# wl_phy_ana_pg_secure register map
Vendor: Texas Instruments
Registers are 32-bit, access per field, reset 0x0 unless marked. A register's access mark holds for its fields unless they carry their own. Offsets are as the file gives them; [hi:lo] are bit positions; {n}, {i} and the like mark numbered series.

## wl_phy_ana_pg_secure (part 2 of 3)
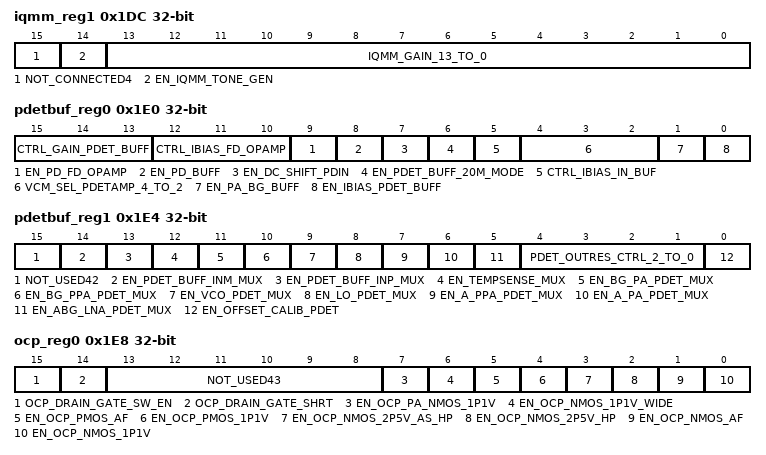
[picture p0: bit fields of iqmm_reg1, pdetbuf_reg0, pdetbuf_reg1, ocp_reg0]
0x1DC iqmm_reg1 — Gain Control bits for IQMM Block
  [15] NOT_CONNECTED4 rw — Not Connected
  [14] EN_IQMM_TONE_GEN rw — Enable the IQMM Block at the Output Tank of LNA
  [13:0] IQMM_GAIN_13_TO_0 rw — Gain Control bits for IQMM Block
0x1E0 pdetbuf_reg0 — Enable IBIAS
  [15:13] CTRL_GAIN_PDET_BUFF rw — Gain control bits for PDET_BUFFER 000 - 8 (18dB) 001 - 5 (14dB) 010 - 4 (12dB) 011 - 2 (6dB) 100 - 1 (0dB) 101 - 0.5 (-6dB) 110 - NA 111 - NA
  [12:10] CTRL_IBIAS_FD_OPAMP rw — Control the bias current in Differential Opamp_ in 12.5uA steps 001 - 12.5uA 100 - 50uA (default) 101 - 62.5uA 110 - 75uA 111 - 87.5uA
  [9] EN_PD_FD_OPAMP rw — Enable Differential Opamp
  [8] EN_PD_BUFF rw — Enable Input Buffers (both Plus and Minus)
  [7] EN_DC_SHIFT_PDIN rw — Enable DC level shift at the PDET_BUFF input_ to reduce the DC by 250mV nominally Suggested if the input levels are more than 600mV. Enabling this block will have 1.2dB attenuation.
  [6] EN_PDET_BUFF_20M_MODE rw — Enable 20M Mode
  [5] CTRL_IBIAS_IN_BUF rw — Increase Input Buffer bias current by 25%
  [4:2] VCM_SEL_PDETAMP_4_TO_2 rw — Select bits for setting the VCM of the PDET_BUFF Output (values are provided for Vref=800mV) 111 - 800mV 110 - 750mV 101 - 700mV 100 - 650mV (default) 011 - 600mV 010 - 550mV 001 - 500mV 000 - 450mV
  [1] EN_PA_BG_BUFF rw — Enable BG BUF (which provides the common mode voltage for setting the PDET_BUFF Output)
  [0] EN_IBIAS_PDET_BUFF rw — Enable IBIAS
0x1E4 pdetbuf_reg1 — Enable Offset calibration switch connected between INP and INM of PDET_BUFF
  [15] NOT_USED42 rw — Spare bit
  [14] EN_PDET_BUFF_INM_MUX rw — Connect PDET_BUFF INM to PDET_TEST_OUT
  [13] EN_PDET_BUFF_INP_MUX rw — Connect PDET_BUFF INP to PDET_TEST_OUT
  [12] EN_TEMPSENSE_MUX rw — Connect RFCIO TSense output to PDET_BUFF inputs
  [11] EN_BG_PA_PDET_MUX rw — Connect BG PA PDet output to PDET_BUFF inputs
  [10] EN_BG_PPA_PDET_MUX rw — Connect BG PPA or BG Mixer PDet output to PDET_BUFF inputs
  [9] EN_VCO_PDET_MUX rw — Connect VCO PDet output to PDET_BUFF inputs
  [8] EN_LO_PDET_MUX rw — Connect A LO Gen PDet output to PDET_BUFF inputs
  [7] EN_A_PPA_PDET_MUX rw — Connect A PPA or A Mixer PDet output to PDET_BUFF inputs
  [6] EN_A_PA_PDET_MUX rw — Connect A PA PDet output to PDET_BUFF inputs
  [5] EN_ABG_LNA_PDET_MUX rw — Connect BG and A LNA PDet output to PDET_BUFF inputs
  [4:1] PDET_OUTRES_CTRL_2_TO_0 rw — Trim bits for the 32k resistor at PD_TOP Output (which is connected to Rx_IFA2 virtual ground) 0000 - Lowest Res 1000 - Default 1111 - Higest Res
  [0] EN_OFFSET_CALIB_PDET rw — Enable Offset calibration switch connected between INP and INM of PDET_BUFF
0x1E8 ocp_reg0 reset not defined — Enable OCP NMOS 1.1V transistor
  [15] OCP_DRAIN_GATE_SW_EN rw — Enable the drain and gate switches of OCP transistors
  [14] OCP_DRAIN_GATE_SHRT rw — Short drain and gate nodes of OCP transistors
  [13:8] NOT_USED43 rw — Spare bits
  [7] EN_OCP_PA_NMOS_1P1V rw — Enable OCP_PA NMOS 1.1V transistor
  [6] EN_OCP_NMOS_1P1V_WIDE rw — Enable OCP NMOS 1.1V Wide transistor
  [5] EN_OCP_PMOS_AF rw — Enable OCP PMOS AF transistor
  [4] EN_OCP_PMOS_1P1V rw — Enable OCP PMOS 1.1V transistor
  [3] EN_OCP_NMOS_2P5V_AS_HP rw — Enable OCP NMOS 2.5V AS HP transistor
  [2] EN_OCP_NMOS_2P5V_HP rw — Enable OCP NMOS 2.5V HP transistor
  [1] EN_OCP_NMOS_AF rw — Enable OCP NMOS AF transistor
  [0] EN_OCP_NMOS_1P1V rw — Enable OCP NMOS 1.1V transistor
0x1EC ocp_reg1 reset 0x4F004F — Not used
  [15:0] OCP_REG1_15_0 rw
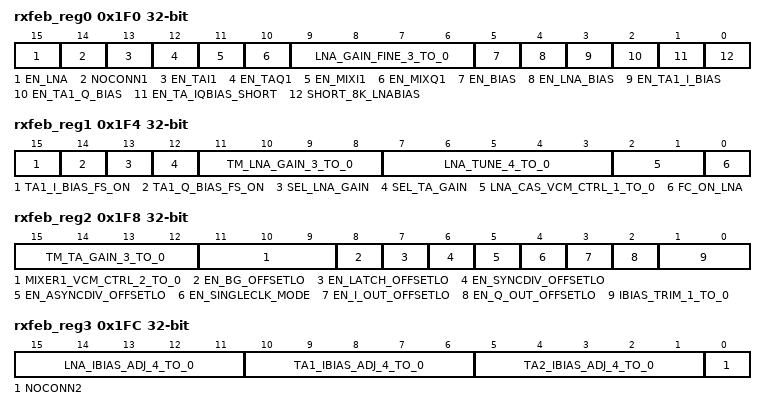
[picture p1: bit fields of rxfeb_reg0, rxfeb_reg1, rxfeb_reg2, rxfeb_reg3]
0x1F0 rxfeb_reg0 — Reduction of LNA bias resistance
  [15] EN_LNA rw — Enable LNA
  [14] NOCONN1 rw — Not Connected
  [13] EN_TAI1 rw — Enable TA I-Channel
  [12] EN_TAQ1 rw — Enable TA Q-Channel
  [11] EN_MIXI1 rw — Enable Mixer I-Channel
  [10] EN_MIXQ1 rw — Enable Mixer Q-Channel
  [9:6] LNA_GAIN_FINE_3_TO_0 rw — Fine Control for LNA Gain Thermometric coded Each bit is LSB of LNA Gain
  [5] EN_BIAS rw — Enable Bias Block
  [4] EN_LNA_BIAS rw — Enable LNA Bias in the Bias Block
  [3] EN_TA1_I_BIAS rw — Enable TA I Channel Bias in the Bias Block
  [2] EN_TA1_Q_BIAS rw — Enable TA Q Channel Bias in the Bias Block
  [1] EN_TA_IQBIAS_SHORT rw — Enable shorting of TA I and Q bias
  [0] SHORT_8K_LNABIAS rw — Reduction of LNA bias resistance
0x1F4 rxfeb_reg1 — Enable Fast Charge LNA
  [15] TA1_I_BIAS_FS_ON rw — Enable Fast Charge TA I-Channel
  [14] TA1_Q_BIAS_FS_ON rw — Enable Fast Charge TA Q-Channel
  [13] SEL_LNA_GAIN rw — Select the LNA gain bits 0 - register bits (TM_LNA_GAIN) will be applied 1 - modem control will be applied
  [12] SEL_TA_GAIN rw — Select the TA gain bits 0 - register bits (TM_TA_GAIN) will be applied 1 - modem control will be applied
  [11:8] TM_LNA_GAIN_3_TO_0 rw — Gain Control bits for LNA 1111 - Highest Gain (Nom 26dB) 0111 - m6dB Gain 0011 - m12dB Gain 0001 - m18dB Gain 0000 - m24dB Gain Gain DNL can vary
  [7:3] LNA_TUNE_4_TO_0 rw — Lna capbank control 00000 - Lowest cap_ Highest frequency tuned 11111 - Highest cap_ lowest frequency tuned 01011 - Nom tunes to 2.45G
  [2:1] LNA_CAS_VCM_CTRL_1_TO_0 rw — Lna cascode gate voltage control 11 - VDDA (1.3V) 10 - 1.2V 01 - 1.1V 00 - 1V
  [0] FC_ON_LNA rw — Enable Fast Charge LNA
0x1F8 rxfeb_reg2 — Control bits to trim the current entering the Bias Block 00 - 50u Ref current (default) 01 - 25u Ref current 10 - 100u Ref current 11 - 33u Ref current
  [15:12] TM_TA_GAIN_3_TO_0 rw — Gain Control for TA 1111 - Highest Gain (Nom 30dB with IFA1) 0111 - m6dB Gain 0011 - m12dB Gain 0001 - m18dB Gain
  [11:9] MIXER1_VCM_CTRL_2_TO_0 rw — Vcm Control for Mixer 111 - 1.21V 110 - 1.13V 101 - 1V 100 - 0.975V 011 - 0.89V 010 - 0.81V 001 - 0.731V 000 - 0.65V
  [8] EN_BG_OFFSETLO rw — Enable offset LO
  [7] EN_LATCH_OFFSETLO rw — Enable latch (To fix starting phase)
  [6] EN_SYNCDIV_OFFSETLO rw — Enable for Synchronous startup mode
  [5] EN_ASYNCDIV_OFFSETLO rw — Enable for Asynchronous startup mode
  [4] EN_SINGLECLK_MODE rw — Enable for Single ended LO input mode 0 - Differential LO input 1 - Single ended LO input
  [3] EN_I_OUT_OFFSETLO rw — Enable for I channel output
  [2] EN_Q_OUT_OFFSETLO rw — Enable for Q channel output
  [1:0] IBIAS_TRIM_1_TO_0 rw — Control bits to trim the current entering the Bias Block 00 - 50u Ref current (default) 01 - 25u Ref current 10 - 100u Ref current 11 - 33u Ref current
0x1FC rxfeb_reg3 — Not connected
  [15:11] LNA_IBIAS_ADJ_4_TO_0 rw — Control for bias of LNA Binary arrangement with ILSB = 20u (Nom)
  [10:6] TA1_IBIAS_ADJ_4_TO_0 rw — Control for bias of TA I Channel Binary arrangement with ILSB = 5u (Nom)
  [5:1] TA2_IBIAS_ADJ_4_TO_0 rw — Control for bias of TA Q Channel Binary Arrangement with ILSB=5u (Nom)
  [0] NOCONN2 rw — Not connected
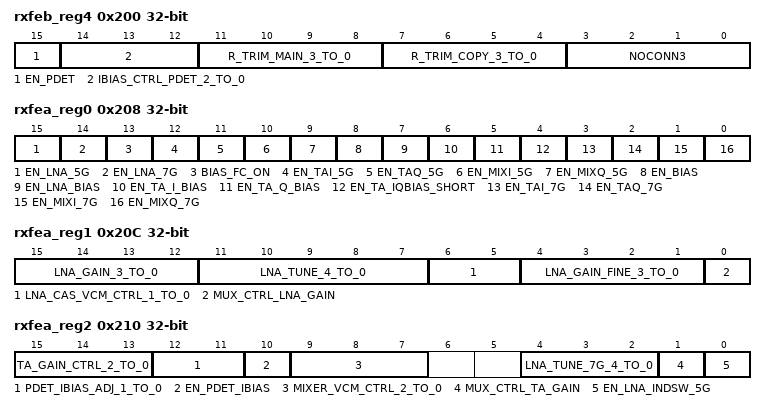
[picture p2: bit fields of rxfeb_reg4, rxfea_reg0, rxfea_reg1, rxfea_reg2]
0x200 rxfeb_reg4 — Not connected
  [15] EN_PDET rw — Enable bit for PDET at LNA output
  [14:12] IBIAS_CTRL_PDET_2_TO_0 rw — Ibias control for PDET at LNA output
  [11:8] R_TRIM_MAIN_3_TO_0 rw — Resistor trim bits for the main branch
  [7:4] R_TRIM_COPY_3_TO_0 rw — Resistor trim bits for the replica branch
  [3:0] NOCONN3 rw — Not connected
0x204 rxpdetb_reg0 reset 0x210021 — MEM_RXPDETB_REG0
  [15:0] RXPDETB_REG0_15_0 rw
0x208 rxfea_reg0 — Enable bit for 7G P-Mixer Q-Channel
  [15] EN_LNA_5G rw — Enable bit for LNA 5G
  [14] EN_LNA_7G rw — Enable bit for LNA 7G
  [13] BIAS_FC_ON rw — Enable bit for Fast Charge LNA
  [12] EN_TAI_5G rw — Enable bit for 5G TA I-Channel
  [11] EN_TAQ_5G rw — Enable bit for 5G TA Q-Channel
  [10] EN_MIXI_5G rw — Enable bit for 5G P-Mixer I-Channel
  [9] EN_MIXQ_5G rw — Enable bit for 5G P-Mixer Q-Channel
  [8] EN_BIAS rw — Enable bit for Bias Block
  [7] EN_LNA_BIAS rw — Enable bit for LNA Bias in the Bias Block
  [6] EN_TA_I_BIAS rw — Enable bit for TA I ch Bias in the Bias Block
  [5] EN_TA_Q_BIAS rw — Enable bit for TA Q ch Bias in the Bias Block
  [4] EN_TA_IQBIAS_SHORT rw — Enable TA_IQBIAS_SHORT
  [3] EN_TAI_7G rw — Enable bit for 7G TA I-Channel
  [2] EN_TAQ_7G rw — Enable bit for 7G TA Q-Channel
  [1] EN_MIXI_7G rw — Enable bit for 7G P-Mixer I-Channel
  [0] EN_MIXQ_7G rw — Enable bit for 7G P-Mixer Q-Channel
0x20C rxfea_reg1 — Mux Control to select either Modem Input or Register Input for LNA Gain 0 - Modem Input 1 - Register Input
  [15:12] LNA_GAIN_3_TO_0 rw — Gain Control bits for LNA 1111 - Highest Gain (Nom 23dB) 0111 - m6dB Gain 0011 - m12dB Gain 0001 - m18dB Gain 0000 - m24dB Gain Gain DNL can vary
  [11:7] LNA_TUNE_4_TO_0 rw — Lna capbank control for 5G 00000 - Lowest cap _ Highest frequency tuned 11111 - Highest cap _ lowest frequency tuned 01111 - Nom tunes to 5G
  [6:5] LNA_CAS_VCM_CTRL_1_TO_0 rw — Lna cascode gate voltage control 11 - VDD(1.3V) 10 - 1.2V 01 - 1.1V 00 - 1V
  [4:1] LNA_GAIN_FINE_3_TO_0 rw — Fine Control for LNA Gain Thermometric coded Each bit is LSB of LNA Gain Default - 2*LSB On
  [0] MUX_CTRL_LNA_GAIN rw — Mux Control to select either Modem Input or Register Input for LNA Gain 0 - Modem Input 1 - Register Input
0x210 rxfea_reg2 — In 5G mode_ enable the switch to short 7G coil to supply
  [15:13] TA_GAIN_CTRL_2_TO_0 rw — Gain Control for TA I Channel 111- Highest Gain ( Nom 30dB with IFA1) 011- m6dB Gain 001 - m12dB Gain 000 - m18dB Gain
  [12:11] PDET_IBIAS_ADJ_1_TO_0 rw — Control the bias current into the PDET Block at the Output of LNA 2 - bit Binary arrangement 10 - 10uA (Nominal) 11 - 15uA 01- 5uA
  [10] EN_PDET_IBIAS rw — Enable the Ibias for PDET Block at the output of LNA
  [9:7] MIXER_VCM_CTRL_2_TO_0 rw — Vcm Control for Pmixer 111 - 1.21V 110 - 1.13V 101 - 1V 100 - 0.975V 011 - 0.89V 010 - 0.81V 001 - 0.731V 000 - 0.65V
  [4:2] LNA_TUNE_7G_4_TO_0 rw — Lna capbank control for 7G 00000 - Lowest cap _ Highest frequency tuned 11111 - Highest cap _ lowest frequency tuned 01111 - Nom tunes to 7G
  [1] MUX_CTRL_TA_GAIN rw — Mux Control to select either Modem Input or Register Input for TA Gain 0 - Modem Input 1 - Register Input
  [0] EN_LNA_INDSW_5G rw — In 5G mode_ enable the switch to short 7G coil to supply
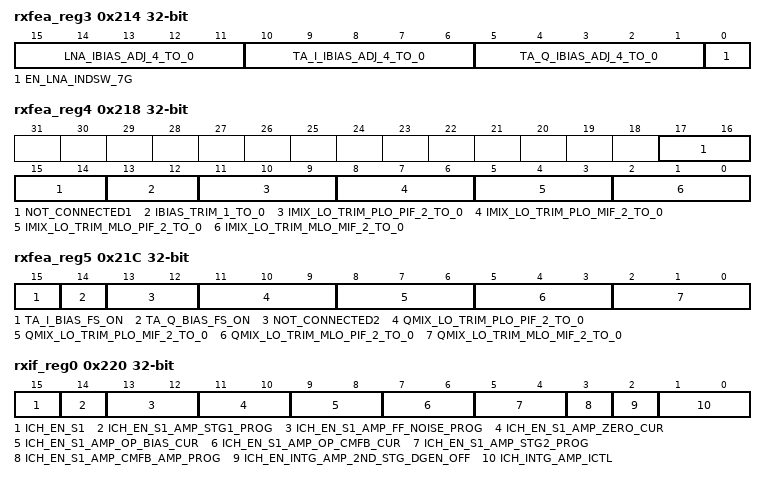
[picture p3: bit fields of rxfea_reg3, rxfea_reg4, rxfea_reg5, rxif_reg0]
0x214 rxfea_reg3 — In 7G mode_ enable the switch to short 5G coil to supply
  [15:11] LNA_IBIAS_ADJ_4_TO_0 rw — Control for bias of A LNA Binary arrangement with ILSB = 40u (Nom)
  [10:6] TA_I_IBIAS_ADJ_4_TO_0 rw — Control for bias of TA I Channel Binary arrangement with ILSB = 5u (Nom)
  [5:1] TA_Q_IBIAS_ADJ_4_TO_0 rw — Control for bias of TA Q Channel Binary Arrangement with ILSB=5u (Nom)
  [0] EN_LNA_INDSW_7G rw — In 7G mode_ enable the switch to short 5G coil to supply
0x218 rxfea_reg4 — Trim control for PMIX Ich connected to LOM and IFM . Coarse Trim decides the tap point .This is Fine Trim. 100-Mid code 011 - 10mV Lower 101- 10mV higher
  [17:14] NOT_CONNECTED1 rw — Not Connected
  [13:12] IBIAS_TRIM_1_TO_0 rw — Control bits to trim the current entering the Bias Block 00 - 50u Ref current(default) 01 - 25u Ref current 10 - 100u Ref current 11 - 33u Ref current
  [11:9] IMIX_LO_TRIM_PLO_PIF_2_TO_0 rw — Trim control for PMIX Ich connected to LOP and IFP . Coarse Trim decides the tap point .This is Fine Trim. 100-Mid code 011 - 10mV Lower 101- 10mV higher
  [8:6] IMIX_LO_TRIM_PLO_MIF_2_TO_0 rw — Trim control for PMIX Ich connected to LOP and IFM . Coarse Trim decides the tap point .This is Fine Trim. 100-Mid code 011 - 10mV Lower 101- 10mV higher
  [5:3] IMIX_LO_TRIM_MLO_PIF_2_TO_0 rw — Trim control for PMIX Ich connected to LOM and IFP . Coarse Trim decides the tap point .This is Fine Trim. 100-Mid code 011 - 10mV Lower 101- 10mV higher
  [2:0] IMIX_LO_TRIM_MLO_MIF_2_TO_0 rw — Trim control for PMIX Ich connected to LOM and IFM . Coarse Trim decides the tap point .This is Fine Trim. 100-Mid code 011 - 10mV Lower 101- 10mV higher
0x21C rxfea_reg5 — Trim control for PMIX Qch connected to LOM and IFM . Coarse Trim decides the tap point .This is Fine Trim. 100-Mid code 011 - 10mV Lower 101- 10mV higher
  [15] TA_I_BIAS_FS_ON rw — 0
  [14] TA_Q_BIAS_FS_ON rw — 0
  [13:12] NOT_CONNECTED2 rw — Not Connected
  [11:9] QMIX_LO_TRIM_PLO_PIF_2_TO_0 rw — Trim control for PMIX Qch connected to LOP and IFP . Coarse Trim decides the tap point .This is Fine Trim. 100-Mid code 011 - 10mV Lower 101- 10mV higher
  [8:6] QMIX_LO_TRIM_PLO_MIF_2_TO_0 rw — Trim control for PMIX Qch connected to LOP and IFM . Coarse Trim decides the tap point .This is Fine Trim. 100-Mid code 011 - 10mV Lower 101- 10mV higher
  [5:3] QMIX_LO_TRIM_MLO_PIF_2_TO_0 rw — Trim control for PMIX Qch connected to LOM and IFP . Coarse Trim decides the tap point .This is Fine Trim. 100-Mid code 011 - 10mV Lower 101- 10mV higher
  [2:0] QMIX_LO_TRIM_MLO_MIF_2_TO_0 rw — Trim control for PMIX Qch connected to LOM and IFM . Coarse Trim decides the tap point .This is Fine Trim. 100-Mid code 011 - 10mV Lower 101- 10mV higher
0x220 rxif_reg0 — INTG Bias current Programmability 00=8uA (8_10) 01=10uA (8_8) 10=11.4uA (8_7) 11=13.3uA(8_6)
  [15] ICH_EN_S1 rw — Enable Integrator
  [14] ICH_EN_S1_AMP_STG1_PROG rw — Second Arm of INT Stage 1- Gain Programmability
  [13:12] ICH_EN_S1_AMP_FF_NOISE_PROG rw — INTG Active zero -(no of gm_gm stage arms) 00= Active Zero Disabled 1_01 = One ARM 11= Both ARMs
  [11:10] ICH_EN_S1_AMP_ZERO_CUR rw — Active Zero NMOS Device (S2 of Main AMP) ARMS 00= No Arm 01_10=One ARM 11= Both ARMS
  [9:8] ICH_EN_S1_AMP_OP_BIAS_CUR rw — INTG S2 current 00= Base Current 01=+100uA 11= +200uA
  [7:6] ICH_EN_S1_AMP_OP_CMFB_CUR rw — CMFB Stage 2 (NMOS) arms
  [5:4] ICH_EN_S1_AMP_STG2_PROG rw — Stage 2 Number of Arms 00= No Arm 01_10=One ARM 11= Both ARMS
  [3] ICH_EN_S1_AMP_CMFB_AMP_PROG rw — CMFB Stage 1 arms 0 Single ARM 1 Both ARMS
  [2] ICH_EN_INTG_AMP_2ND_STG_DGEN_OFF rw — 0= DGEN ENABLE 1= DGEN ENABLE
  [1:0] ICH_INTG_AMP_ICTL rw — INTG Bias current Programmability 00=8uA (8_10) 01=10uA (8_8) 10=11.4uA (8_7) 11=13.3uA(8_6)
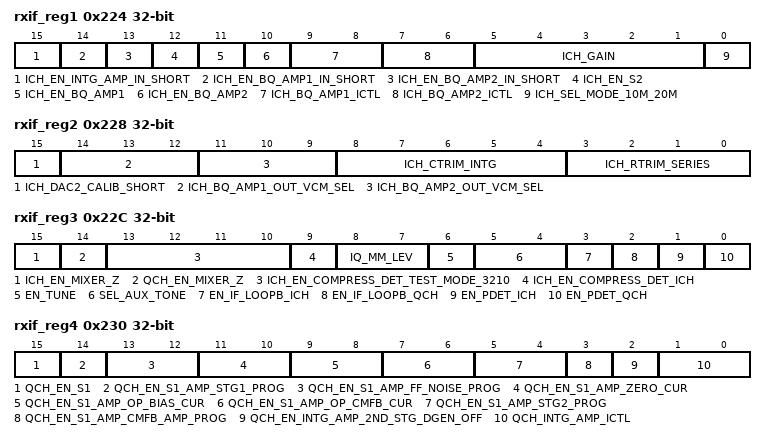
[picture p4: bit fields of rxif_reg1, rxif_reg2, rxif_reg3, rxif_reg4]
0x224 rxif_reg1 — Cap Mode 0 = HIGH CAP 1= LOW CAP
  [15] ICH_EN_INTG_AMP_IN_SHORT rw — Pull down INTG Inp
  [14] ICH_EN_BQ_AMP1_IN_SHORT rw — Pull down BQ1 Inp
  [13] ICH_EN_BQ_AMP2_IN_SHORT rw — Pull down BQ2 Inp
  [12] ICH_EN_S2 rw — Enable BiQuad
  [11] ICH_EN_BQ_AMP1 rw — ENABLE BQ1 amp
  [10] ICH_EN_BQ_AMP2 rw — ENABLE BQ2 amp
  [9:8] ICH_BQ_AMP1_ICTL rw — Biquad Bias current Programmability 00=8uA (8_10) 01=10uA (8_8) 10=11.4uA (8_7) 11=13.3uA(8_6)
  [7:6] ICH_BQ_AMP2_ICTL rw — Biquad Bias current Programmability 00=8uA (8_10) 01=10uA (8_8) 10=11.4uA (8_7) 11=13.3uA(8_6)
  [5:1] ICH_GAIN rw — Gain 00000=-7dB 00001=-6dB 00010=-5dB... 00101=-2dB (NOM MIN) 01101=6dB (NOM MAX) 10010=11dB 10011=12dB 10100=13dB 10101=14dB 10110=15dB 10111=16dB 11000=17dB (AUX RX MODE) 11001=20dB (AUX RX MODE) 11010=23dB (AUX RX MODE)
  [0] ICH_SEL_MODE_10M_20M rw — Cap Mode 0 = HIGH CAP 1= LOW CAP
0x228 rxif_reg2 — Sereis Rtrrim 0000 MIN R=( WEAK CORNER) 1001 NOM R 1111 MAX R (STRONG CORNER)
  [15] ICH_DAC2_CALIB_SHORT rw — Short imp inm of Biquad
  [14:12] ICH_BQ_AMP1_OUT_VCM_SEL rw — VCM BQ amp1 000=330mV 001=360mV 100=450mV (NOM) 111=540mV
  [11:9] ICH_BQ_AMP2_OUT_VCM_SEL rw — VCM BQ amp2 000=330mV 001=360mV 100=450mV (NOM) 111=540mV
  [8:4] ICH_CTRIM_INTG rw — Cint Cap tune 00000= Min CAP 01001= NOM CAP 11111= MAX CAP
  [3:0] ICH_RTRIM_SERIES rw — Sereis Rtrrim 0000 MIN R=( WEAK CORNER) 1001 NOM R 1111 MAX R (STRONG CORNER)
0x22C rxif_reg3 — ENABLE PDET
  [15] ICH_EN_MIXER_Z rw — Add input impedance to INTG
  [14] QCH_EN_MIXER_Z rw — Add input impedance to INTG
  [13:10] ICH_EN_COMPRESS_DET_TEST_MODE_3210 rw — Mux Compress det out on test mode 0000= NO O_p 0001= DETECTOR O_P To TEST PIN 0010= Compare Ref O_P to Test Pin 0100=Compare input (PEAK det) O_P to Test PIN 1000= VCM input to Test PIN
  [9] ICH_EN_COMPRESS_DET_ICH rw — EN Compress DET
  [8:7] IQ_MM_LEV rw — BW calib DAC power 00=5uA 01=10uA 10=15uA 11=20uA
  [6] EN_TUNE rw — EN BW Calib DAC
  [5:4] SEL_AUX_TONE rw — Bandwidth calib DAC FREQ SEL 00=2.5MHz 01=5MHz 10=10MHz 11=20MHz
  [3] EN_IF_LOOPB_ICH rw — EN TX Loopback
  [2] EN_IF_LOOPB_QCH rw — EN TX Loopback
  [1] EN_PDET_ICH rw — ENABLE PDET
  [0] EN_PDET_QCH rw — ENABLE PDET
0x230 rxif_reg4 — INTG Bias current Programmability 00=8uA (8_10) 01=10uA (8_8) 10=11.4uA (8_7) 11=13.3uA(8_6)
  [15] QCH_EN_S1 rw — Enable Integrator
  [14] QCH_EN_S1_AMP_STG1_PROG rw — Second Arm of INT Stage 1- Gain Programmability
  [13:12] QCH_EN_S1_AMP_FF_NOISE_PROG rw — INTG Active zero -(no of gm_gm stage arms) 00= Active Zero Disabled 1_01 = One ARM 11= Both ARMs
  [11:10] QCH_EN_S1_AMP_ZERO_CUR rw — Active Zero NMOS Device (S2 of Main AMP) ARMS 00= No Arm 01_10=One ARM 11= Both ARMS
  [9:8] QCH_EN_S1_AMP_OP_BIAS_CUR rw — INTG S2 current 00= Base Current 01=+100uA 11= +200uA
  [7:6] QCH_EN_S1_AMP_OP_CMFB_CUR rw — CMFB Stage 2 (NMOS) arms
  [5:4] QCH_EN_S1_AMP_STG2_PROG rw — Stage 2 Number of Arms 00= No Arm 01_10=One ARM 11= Both ARMS
  [3] QCH_EN_S1_AMP_CMFB_AMP_PROG rw — CMFB Stage 1 arms 0 Single ARM 1 Both ARMS
  [2] QCH_EN_INTG_AMP_2ND_STG_DGEN_OFF rw — 0= DGEN ENABLE 1= DGEN ENABLE
  [1:0] QCH_INTG_AMP_ICTL rw — INTG Bias current Programmability 00=8uA (8_10) 01=10uA (8_8) 10=11.4uA (8_7) 11=13.3uA(8_6)
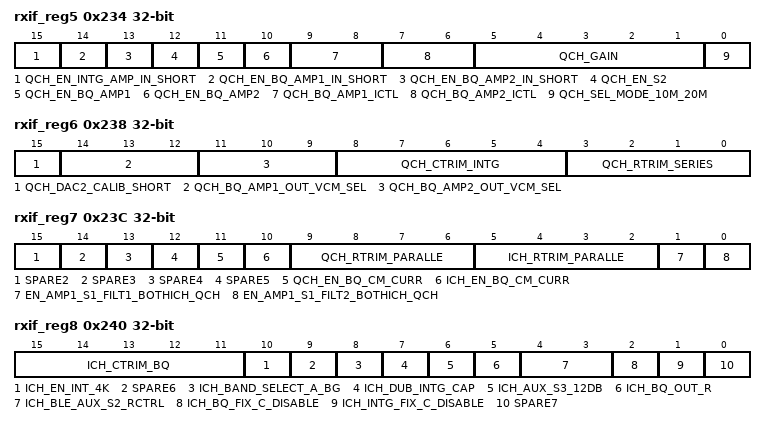
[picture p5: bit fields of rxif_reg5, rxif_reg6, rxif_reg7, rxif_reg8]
0x234 rxif_reg5 — Cap Mode 0 = HIGH CAP 1= LOW CAP
  [15] QCH_EN_INTG_AMP_IN_SHORT rw — Pull down INTG Inp
  [14] QCH_EN_BQ_AMP1_IN_SHORT rw — Pull down BQ1 Inp
  [13] QCH_EN_BQ_AMP2_IN_SHORT rw — Pull down BQ2 Inp
  [12] QCH_EN_S2 rw — Enable BiQuad
  [11] QCH_EN_BQ_AMP1 rw — ENABLE BQ1 amp
  [10] QCH_EN_BQ_AMP2 rw — ENABLE BQ2 amp
  [9:8] QCH_BQ_AMP1_ICTL rw — Biquad Bias current Programmability 00=8uA (8_10) 01=10uA (8_8) 10=11.4uA (8_7) 11=13.3uA(8_6)
  [7:6] QCH_BQ_AMP2_ICTL rw — Biquad Bias current Programmability 00=8uA (8_10) 01=10uA (8_8) 10=11.4uA (8_7) 11=13.3uA(8_6)
  [5:1] QCH_GAIN rw — Gain 00000=-7dB 00001=-6dB 00010=-5dB... 00101=-2dB (NOM MIN) 01101=6dB (NOM MAX) 10010=11dB 10011=12dB 10100=13dB 10101=14dB 10110=15dB 10111=16dB 11000=17dB (AUX RX MODE) 11001=20dB (AUX RX MODE) 11010=23dB (AUX RX MODE)
  [0] QCH_SEL_MODE_10M_20M rw — Cap Mode 0 = HIGH CAP 1= LOW CAP
0x238 rxif_reg6 — Sereis Rtrrim 0000 MIN R=( WEAK CORNER) 1001 NOM R 1111 MAX R (STRONG CORNER)
  [15] QCH_DAC2_CALIB_SHORT rw — Short imp inm of Biquad
  [14:12] QCH_BQ_AMP1_OUT_VCM_SEL rw — VCM BQ amp1 000=330mV 001=360mV 100=450mV (NOM) 111=540mV
  [11:9] QCH_BQ_AMP2_OUT_VCM_SEL rw — VCM BQ amp2 000=330mV 001=360mV 100=450mV (NOM) 111=540mV
  [8:4] QCH_CTRIM_INTG rw — Cint Cap tune 00000= Min CAP 01001= NOM CAP 11111= MAX CAP
  [3:0] QCH_RTRIM_SERIES rw — Sereis Rtrrim 0000 MIN R=( WEAK CORNER) 1001 NOM R 1111 MAX R (STRONG CORNER)
0x23C rxif_reg7 — EN RC2(Low Cap) at intg S1 O_p
  [17-n] SPARE{n} rw (n=2..5) — SPARE
  [11] QCH_EN_BQ_CM_CURR rw — Q Boost BQ input CM
  [10] ICH_EN_BQ_CM_CURR rw — I Boost BQ input CM
  [9:6] QCH_RTRIM_PARALLE rw — Parallel Rtrim 0000= MAX R (STRONG CORNER) 0100= NOM R 1111=MIN R
  [5:2] ICH_RTRIM_PARALLE rw — Parallel Rtrim 0000= MAX R (STRONG CORNER) 0100= NOM R 1111=MIN R
  [1] EN_AMP1_S1_FILT1_BOTHICH_QCH rw — EN Low RC1 (High cap) at INTG S1 O_p
  [0] EN_AMP1_S1_FILT2_BOTHICH_QCH rw — EN RC2(Low Cap) at intg S1 O_p
0x240 rxif_reg8
  [15:11] ICH_CTRIM_BQ rw — C BQ Cap tune 00000= MIN CAP 01001=NOM CAP 11111= MAX CAP
  [10] ICH_EN_INT_4K rw — INTG RFb 4k_8k 0=8k 1=4k
  [9] SPARE6 rw — Input path Select Rx_ Aux Rx 0= WLAN_BLE Rx 1= AUX Rx
  [8] ICH_BAND_SELECT_A_BG rw — Input path select (Band-a_BG) 0= BG 1= A
  [7] ICH_DUB_INTG_CAP rw — INTG C feedback double 0= Normal CAP 1= Double CAP
  [6] ICH_AUX_S3_12DB rw — Aux Rx gain S3 0= Nominal gain 1= +6dB
  [5] ICH_BQ_OUT_R rw — Open biquad outer loop 1= WLAN MODE 0= BLE + AUXRX MODE
  [4:3] ICH_BLE_AUX_S2_RCTRL rw — BQ Amp1 Rfb control 00=16k 01=20.1k 10=25.44k 11=32k
  [2] ICH_BQ_FIX_C_DISABLE rw — Fixed Cap disable BQ
  [1] ICH_INTG_FIX_C_DISABLE rw — Fixed Cap disable INTG
  [0] SPARE7 rw
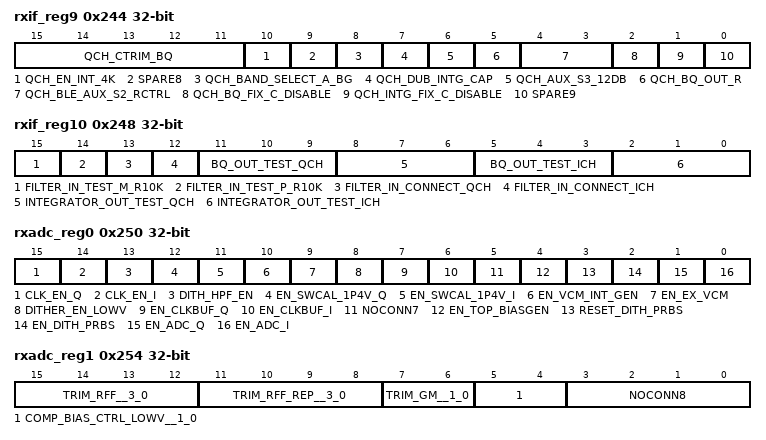
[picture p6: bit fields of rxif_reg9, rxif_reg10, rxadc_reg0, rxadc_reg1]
0x244 rxif_reg9
  [15:11] QCH_CTRIM_BQ rw — C BQ Cap tune 00000= MIN CAP 01001=NOM CAP 11111= MAX CAP
  [10] QCH_EN_INT_4K rw — INTG RFb 4k_8k 0=8k 1=4k
  [9] SPARE8 rw — Input path Select Rx_ Aux Rx 0= WLAN_BLE Rx 1= AUX Rx
  [8] QCH_BAND_SELECT_A_BG rw — Input path select (Band-a_BG) 0= BG 1= A
  [7] QCH_DUB_INTG_CAP rw — INTG C feedback double 0= Normal CAP 1= Double CAP
  [6] QCH_AUX_S3_12DB rw — Aux Rx gain S3 0= Nominal gain 1= +6dB
  [5] QCH_BQ_OUT_R rw — Open biquad outer loop 1= WLAN MODE 0= BLE + AUXRX MODE
  [4:3] QCH_BLE_AUX_S2_RCTRL rw — BQ Amp1 Rfb control 00=16k 01=20.1k 10=25.44k 11=32k
  [2] QCH_BQ_FIX_C_DISABLE rw — Fixed Cap disable BQ
  [1] QCH_INTG_FIX_C_DISABLE rw — Fixed Cap disable INTG
  [0] SPARE9 rw
0x248 rxif_reg10 — 001-EN_I_SENSE 010-EN_V_SENSE 100-EN_EXT_INP through R=400
  [15] FILTER_IN_TEST_M_R10K rw — Connects a 10K R From TestM to GND
  [14] FILTER_IN_TEST_P_R10K rw — Connects a 10K R From TestP to GND
  [13] FILTER_IN_CONNECT_QCH rw — Connects QCH to TestP and TestM
  [12] FILTER_IN_CONNECT_ICH rw — Connects ICH to TestP and TestM
  [11:9] BQ_OUT_TEST_QCH rw — 001-EN_I_SENSE 010-EN_V_SENSE_ADC_TEST_IN 100-EN_EXT_INP through R=8k
  [8:6] INTEGRATOR_OUT_TEST_QCH rw — 001-EN_I_SENSE 010-EN_V_SENSE 100-EN_EXT_INP through R=400
  [5:3] BQ_OUT_TEST_ICH rw — 001-EN_I_SENSE 010-EN_V_SENSE_ADC_TEST_IN 100-EN_EXT_INP through R=8k
  [2:0] INTEGRATOR_OUT_TEST_ICH rw — 001-EN_I_SENSE 010-EN_V_SENSE 100-EN_EXT_INP through R=400
0x24C rxv2i_reg0 reset 0x220022 — MEM_RXV2I_REG0
  [15:0] RXV2I_REG0_15_0 rw
0x250 rxadc_reg0 — I channel
  [15] CLK_EN_Q rw — Q channel
  [14] CLK_EN_I rw — I channel
  [13] DITH_HPF_EN rw — both
  [12] EN_SWCAL_1P4V_Q rw — Q channel
  [11] EN_SWCAL_1P4V_I rw — I channel
  [10] EN_VCM_INT_GEN rw — both
  [9] EN_EX_VCM rw — both
  [8] DITHER_EN_LOWV rw — both
  [7] EN_CLKBUF_Q rw — Q channel
  [6] EN_CLKBUF_I rw — I channel
  [5] NOCONN7 rw
  [4] EN_TOP_BIASGEN rw — both
  [3] RESET_DITH_PRBS rw — both
  [2] EN_DITH_PRBS rw — both
  [1] EN_ADC_Q rw — Q channel
  [0] EN_ADC_I rw — I channel
0x254 rxadc_reg1
  [15:12] TRIM_RFF__3_0 rw — both
  [11:8] TRIM_RFF_REP__3_0 rw — both
  [7:6] TRIM_GM__1_0 rw — Trim Gm
  [5:4] COMP_BIAS_CTRL_LOWV__1_0 rw — both
  [3:0] NOCONN8 rw
0x258 rxadc_reg2 — I channel
  [15:0] TRIM_SWCAL_1P4V_Q__15_0 rw
0x25C rxadc_reg3 — I channel
  [15:0] TRIM_SWCAL_1P4V_I__15_0 rw
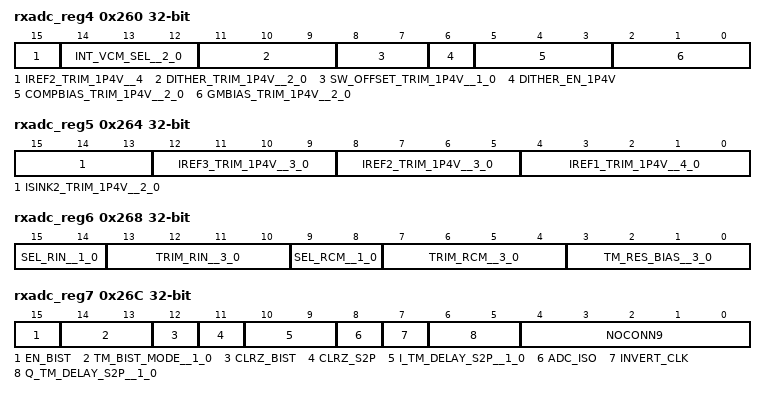
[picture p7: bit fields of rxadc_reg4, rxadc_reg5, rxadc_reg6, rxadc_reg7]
0x260 rxadc_reg4 — Top_Ibias
  [15] IREF2_TRIM_1P4V__4 rw — iref2 trim
  [14:12] INT_VCM_SEL__2_0 rw — int vcm sel
  [11:9] DITHER_TRIM_1P4V__2_0 rw — Top_Ibias
  [8:7] SW_OFFSET_TRIM_1P4V__1_0 rw — Top_Ibias
  [6] DITHER_EN_1P4V rw — Top_Ibias
  [5:3] COMPBIAS_TRIM_1P4V__2_0 rw — Top_Ibias
  [2:0] GMBIAS_TRIM_1P4V__2_0 rw — Top_Ibias
0x264 rxadc_reg5 — Top_Ibias
  [15:13] ISINK2_TRIM_1P4V__2_0 rw — Top_Ibias
  [12:9] IREF3_TRIM_1P4V__3_0 rw — Top_Ibias
  [8:5] IREF2_TRIM_1P4V__3_0 rw — Top_Ibias
  [4:0] IREF1_TRIM_1P4V__4_0 rw — Top_Ibias
0x268 rxadc_reg6 — TM_RES_BIAS
  [15:14] SEL_RIN__1_0 rw — SEL_RIN
  [13:10] TRIM_RIN__3_0 rw — TRIM_RIN
  [9:8] SEL_RCM__1_0 rw — I channel
  [7:4] TRIM_RCM__3_0 rw — Q channel
  [3:0] TM_RES_BIAS__3_0 rw — TM_RES_BIAS
0x26C rxadc_reg7
  [15] EN_BIST rw
  [14:13] TM_BIST_MODE__1_0 rw — TM_BIST_MODE
  [12] CLRZ_BIST rw
  [11] CLRZ_S2P rw
  [10:9] I_TM_DELAY_S2P__1_0 rw — I channel
  [8] ADC_ISO rw
  [7] INVERT_CLK rw
  [6:5] Q_TM_DELAY_S2P__1_0 rw — Q channel
  [4:0] NOCONN9 rw
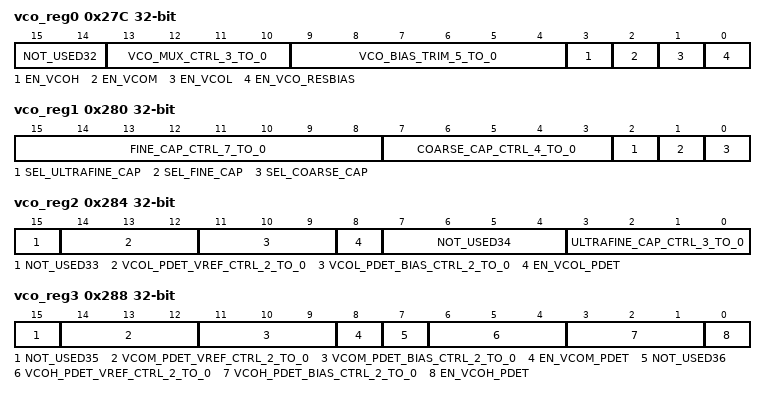
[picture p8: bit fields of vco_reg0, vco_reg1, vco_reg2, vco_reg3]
0x27C vco_reg0 — Enable bit for the VCO Resistor Bias (common for all VCOs)
  [15:14] NOT_USED32 rw — Spare bits
  [13:10] VCO_MUX_CTRL_3_TO_0 rw — Control bits for the VCO MUX_ for selecting different VCO outputs - VCOH - VCOM - VCOL
  [9:4] VCO_BIAS_TRIM_5_TO_0 rw — Trim bits for the VCO Resistor Bias (common control for all VCO currents) Nom_27C_1.3V supply- - 800uA - 1.5mA - 2.7mA - 4.6mA - 7.3mA - 10.5mA
  [3] EN_VCOH rw — Enable bit for the VCOH (8.60-9.50GHz)
  [2] EN_VCOM rw — Enable bit for the VCOM (7.85-8.70GHz)
  [1] EN_VCOL rw — Enable bit for the VCOL (6.40-7.16GHz)
  [0] EN_VCO_RESBIAS rw — Enable bit for the VCO Resistor Bias (common for all VCOs)
0x280 vco_reg1 — Select Coarse Cap control bits to come from 0 - PLL 1 - Register bits (bypass mode)
  [15:8] FINE_CAP_CTRL_7_TO_0 rw — Fine Cap control bits in bypass mode (thermometric arrangement)
  [7:3] COARSE_CAP_CTRL_4_TO_0 rw — Coarse Cap control bits in bypass mode (binary arrangement)
  [2] SEL_ULTRAFINE_CAP rw — Select UltraFine Cap control bits to come from 0 - PLL 1 - Register bits (bypass mode)
  [1] SEL_FINE_CAP rw — Select Fine Cap control bits to come from 0 - PLL 1 - Register bits (bypass mode)
  [0] SEL_COARSE_CAP rw — Select Coarse Cap control bits to come from 0 - PLL 1 - Register bits (bypass mode)
0x284 vco_reg2 — UltraFine Cap control bits in bypass mode (thermometric arrangement)
  [15] NOT_USED33 rw — Spare bit
  [14:12] VCOL_PDET_VREF_CTRL_2_TO_0 rw — Control the VCOL PDet reference voltage by changing the bias diode current_ in steps of 5uA 000 - 10uA 010 - 20uA (default) 111 - 45uA
  [11:9] VCOL_PDET_BIAS_CTRL_2_TO_0 rw — Control the VCOL PDet bias current_ in steps of 5uA 000 - 10uA 010 - 20uA (default) 111 - 45uA
  [8] EN_VCOL_PDET rw — Enable bit for the VCOL PDet
  [7:4] NOT_USED34 rw — Spare bits
  [3:0] ULTRAFINE_CAP_CTRL_3_TO_0 rw — UltraFine Cap control bits in bypass mode (thermometric arrangement)
0x288 vco_reg3 — Enable bit for the VCOH PDet
  [15] NOT_USED35 rw — Spare bit
  [14:12] VCOM_PDET_VREF_CTRL_2_TO_0 rw — Control the VCOM PDet reference voltage by changing the bias diode current_ in steps of 5uA 000 - 10uA 010 - 20uA (default) 111 - 45uA
  [11:9] VCOM_PDET_BIAS_CTRL_2_TO_0 rw — Control the VCOM PDet bias current_ in steps of 5uA 000 - 10uA 010 - 20uA (default) 111 - 45uA
  [8] EN_VCOM_PDET rw — Enable bit for the VCOM PDet
  [7] NOT_USED36 rw — Spare bit
  [6:4] VCOH_PDET_VREF_CTRL_2_TO_0 rw — Control the VCOH PDet reference voltage by changing the bias diode current_ in steps of 5uA 000 - 10uA 010 - 20uA (default) 111 - 45uA
  [3:1] VCOH_PDET_BIAS_CTRL_2_TO_0 rw — Control the VCOH PDet bias current_ in steps of 5uA 000 - 10uA 010 - 20uA (default) 111 - 45uA
  [0] EN_VCOH_PDET rw — Enable bit for the VCOH PDet
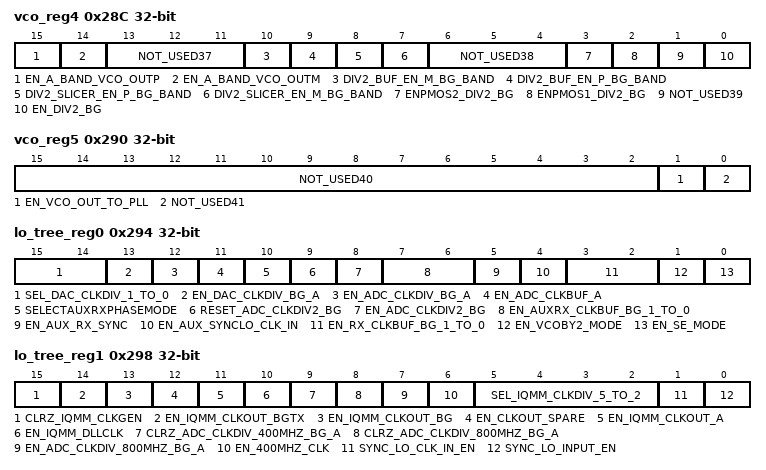
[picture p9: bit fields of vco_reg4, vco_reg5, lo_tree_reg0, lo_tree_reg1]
0x28C vco_reg4 — Enable BG band Div2
  [15] EN_A_BAND_VCO_OUTP rw — Enable VCO_OUTP path to A band LO dist.This needs to be disabled for single ended LO routing mode for vco buffers to a-band
  [14] EN_A_BAND_VCO_OUTM rw — Enable VCO_OUTM path to A band LO dist. This needs to be enabled for single ended LO routing mode for vco buffers to a-band.
  [13:11] NOT_USED37 rw — NOT USED
  [10] DIV2_BUF_EN_M_BG_BAND rw — Enable for OUTM of buf after Slicer (after Div2) for BG band
  [9] DIV2_BUF_EN_P_BG_BAND rw — Enable for OUTP of buf after Slicer (after Div2) for BG band
  [8] DIV2_SLICER_EN_P_BG_BAND rw — Enable for OUTP of Slicer after Div2 for BG band
  [7] DIV2_SLICER_EN_M_BG_BAND rw — Enable for OUTM of Slicer after Div2 for BG band
  [6:4] NOT_USED38 rw — NOT USED
  [3] ENPMOS2_DIV2_BG rw — Enable extra drive for PMOS in BG band Div2 (2X strength)
  [2] ENPMOS1_DIV2_BG rw — Enable extra drive for PMOS in BG band Div2 (1X strength)
  [1] NOT_USED39 rw
  [0] EN_DIV2_BG rw — Enable BG band Div2
0x290 vco_reg5
  [15:2] NOT_USED40 rw — NOT USED
  [1] EN_VCO_OUT_TO_PLL rw — Enable VCO Out to PLL
  [0] NOT_USED41 rw
0x294 lo_tree_reg0 — Enable single ended LO routing mode for VCO clock to a-band
  [15:14] SEL_DAC_CLKDIV_1_TO_0 rw — DAC Divider options 00 - Div4 01 - Div3 10 - Div5 11 - Div3
  [13] EN_DAC_CLKDIV_BG_A rw — Enable the DAC divider
  [12] EN_ADC_CLKDIV_BG_A rw — Enable the final divider (DIV =1 by default) in ADC clock path for both BG and Aband
  [11] EN_ADC_CLKBUF_A rw — Enable for A band ADC clock buffer
  [10] SELECTAUXRXPHASEMODE rw — 0= default phase 1= 90 degree phase change
  [9] RESET_ADC_CLKDIV2_BG rw — Reset ADCCLK div (BG band freq. 3.2G_2)
  [8] EN_ADC_CLKDIV2_BG rw — Enable ADCCLK div (BG band freq. 3.2G_2)
  [7:6] EN_AUXRX_CLKBUF_BG_1_TO_0 rw — Enables for BG band AUXRX clock buffers Bit 7 for P; 6 for M.
  [5] EN_AUX_RX_SYNC rw — Enables Signal for Synchronous Wakeup of AUX Block
  [4] EN_AUX_SYNCLO_CLK_IN rw — Enables DAC clock to go into AUX Rx block
  [3:2] EN_RX_CLKBUF_BG_1_TO_0 rw — Enables for BG band RX clock buffers. Bit 3 for P; 2 for M.
  [1] EN_VCOBY2_MODE rw — Enables for VCO_2 clock getting routed to a-band
  [0] EN_SE_MODE rw — Enable single ended LO routing mode for VCO clock to a-band
0x298 lo_tree_reg1 — Data enable for SYNC LO block in BG band LO TREE
  [15] CLRZ_IQMM_CLKGEN rw — Resets IQMM_CLK FFs
  [14] EN_IQMM_CLKOUT_BGTX rw — Provides cal clock to BG band mixer IQMM module
  [13] EN_IQMM_CLKOUT_BG rw — Provides cal clock to BG band LNA IQMM module
  [12] EN_CLKOUT_SPARE rw — Provides cal clock of same freq as _ or but is presently not routed outside LO_TREE module
  [11] EN_IQMM_CLKOUT_A rw — Provides cal clock to A band LNA IQMM module
  [10] EN_IQMM_DLLCLK rw — Enables DLL clock for IQMM block
  [9] CLRZ_ADC_CLKDIV_400MHZ_BG_A rw — CLRZ for divider (DIV4) to generate 400MHz clock for ADC
  [8] CLRZ_ADC_CLKDIV_800MHZ_BG_A rw — CLRZ for divider (DIV2) to generate 800MHz clock for ADC
  [7] EN_ADC_CLKDIV_800MHZ_BG_A rw — Enables divider (DIV2) to generate 800MHz clock for ADC
  [6] EN_400MHZ_CLK rw — Enables divider (DIV4) to generate 400MHz clock for ADC
  [5:2] SEL_IQMM_CLKDIV_5_TO_2 rw — Selects division ratio for IQMM block output. 0001 = no division; 0010 - divby2 ; 0100 - divby4; 1000 - divby8
  [1] SYNC_LO_CLK_IN_EN rw — Clock enable for SYNC LO block in BG band LO TREE
  [0] SYNC_LO_INPUT_EN rw — Data enable for SYNC LO block in BG band LO TREE
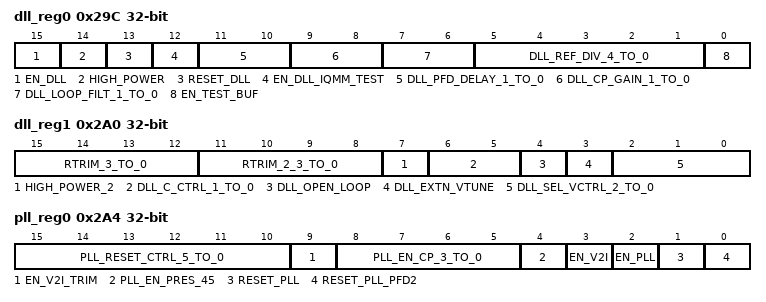
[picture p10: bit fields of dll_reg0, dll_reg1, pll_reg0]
0x29C dll_reg0 — 1' - enables DLL CLK out on TEST pin
  [15] EN_DLL rw — 1' Enable DLL; '0' Disable DLL
  [14] HIGH_POWER rw — 1' Enable High Power; '0' Disable High Power
  [13] RESET_DLL rw — 1' Reset DLL; '0' Disable RESET DLL
  [12] EN_DLL_IQMM_TEST rw — 1' Enables DLL Output for IQMM test
  [11:10] DLL_PFD_DELAY_1_TO_0 rw — 00' - One Nand delay '01' - One Nand delay '10' - One NAND and two inverter delay '11' - Max delay
  [9:8] DLL_CP_GAIN_1_TO_0 rw — CP Gain trim setting 00' - 40uA '10' and '01' - 53uA '11' - 60uA
  [7:6] DLL_LOOP_FILT_1_TO_0 rw
  [5:1] DLL_REF_DIV_4_TO_0 rw — LF Cap control '00' - 3pF (Max cap) '01' and '10' 2pF '11' - 1pF
  [0] EN_TEST_BUF rw — 1' - enables DLL CLK out on TEST pin
0x2A0 dll_reg1 — Select VTUNE voltage from R ladder '000' highest voltage '111' lowest voltage
  [15:12] RTRIM_3_TO_0 rw — RTRIM for Delay cell comparator
  [11:8] RTRIM_2_3_TO_0 rw — RTRIM2 for Delay cell comparator current mirror
  [7] HIGH_POWER_2 rw — increase current in delay cell comparator
  [6:5] DLL_C_CTRL_1_TO_0 rw — Delay cell cap '00' higher delay '11' lowest delay
  [4] DLL_OPEN_LOOP rw — To open the DLL loop
  [3] DLL_EXTN_VTUNE rw — To send a VTUNE to delay cell for debug mode_ from a R ladder
  [2:0] DLL_SEL_VCTRL_2_TO_0 rw — Select VTUNE voltage from R ladder '000' highest voltage '111' lowest voltage
0x2A4 pll_reg0 — Reset Dual PFD when '1'
  [15:10] PLL_RESET_CTRL_5_TO_0 rw — SW_CTRL_EN '0' PLL loop controlled by Synth Dig SW_CTRL_EN '1' PLL loop controlled by bit SW_CTRL - '0' PLL loop closed when is '1' SW_CTRL - '1' PLL loop open when is '1' Delay multiplier after which the SW_CTRL_OUT is made 0
  [9] EN_V2I_TRIM rw — Enable V2I ERR AMP lower current for bias margin
  [8:5] PLL_EN_CP_3_TO_0 rw — enable CP Enable DN switches Enable UP switches Enable DN2 switches for dual PFD mode
  [4] PLL_EN_PRES_45 rw — Enable 4_5 Prescaler
  [3] EN_V2I rw — Enable V2I
  [2] EN_PLL rw — Enable PLL
  [1] RESET_PLL rw — Reset PLL when '1'
  [0] RESET_PLL_PFD2 rw — Reset Dual PFD when '1'
{0x2A4+4i} pll_reg{i} (i=1..3) — SPARE
  [15:0] PLL_REG{i}_15_TO_0 rw
